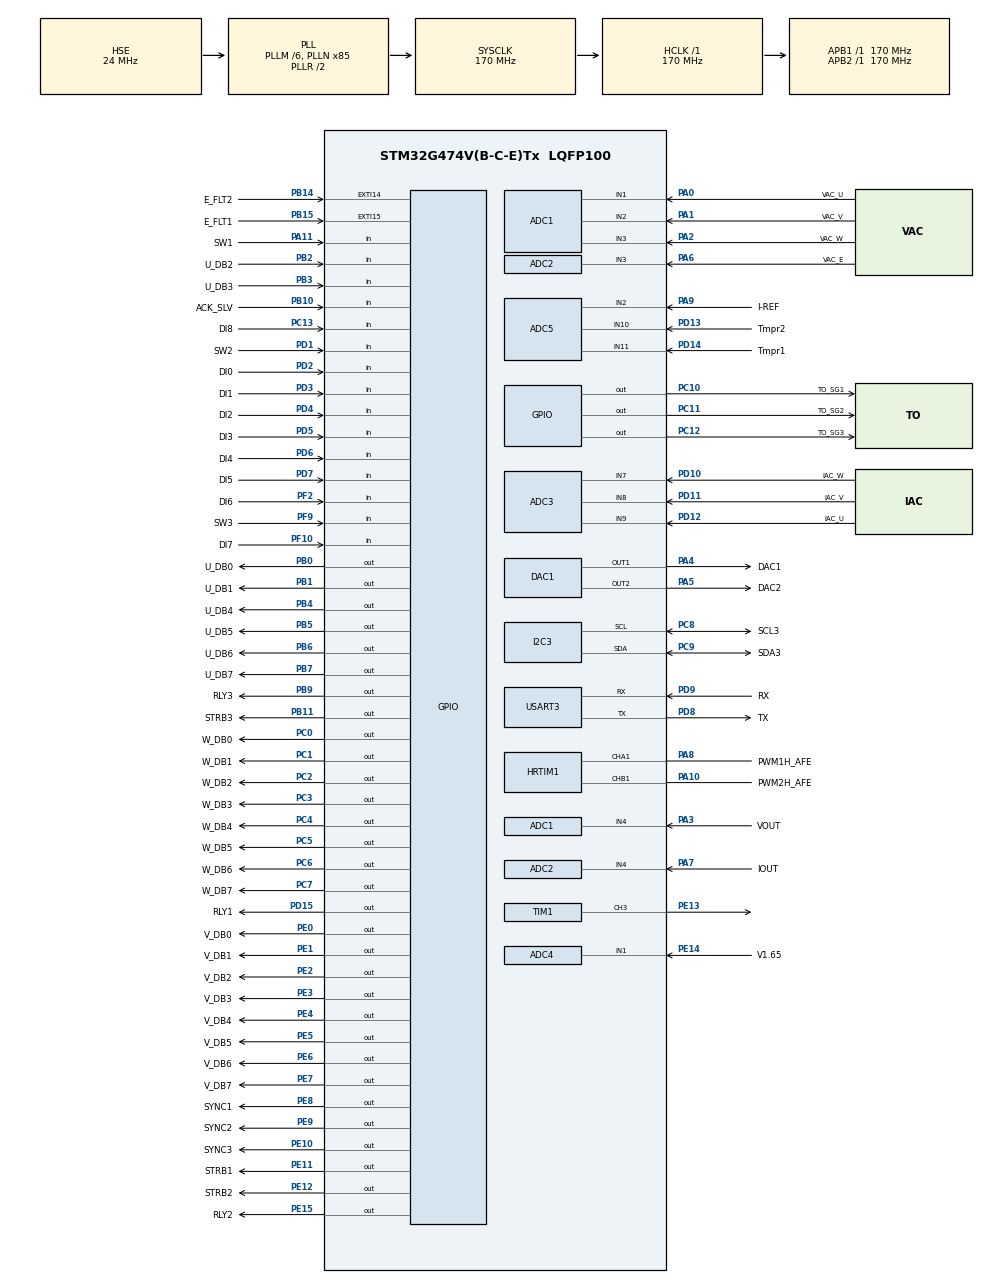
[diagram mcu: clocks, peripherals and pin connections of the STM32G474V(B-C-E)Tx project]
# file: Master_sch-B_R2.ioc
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ADC1.Channel-2\#ChannelRegularConversion=ADC_CHANNEL_1
ADC1.Channel-3\#ChannelRegularConversion=ADC_CHANNEL_3
ADC1.Channel-4\#ChannelRegularConversion=ADC_CHANNEL_2
ADC1.Channel-5\#ChannelRegularConversion=ADC_CHANNEL_4
ADC1.ContinuousConvMode=DISABLE
ADC1.DMAContinuousRequests=ENABLE
ADC1.EOCSelection=ADC_EOC_SEQ_CONV
ADC1.ExternalTrigConv=ADC_EXTERNALTRIG_T3_TRGO
ADC1.NbrOfConversion=4
ADC1.NbrOfConversionFlag=1
ADC1.OffsetNumber-2\#ChannelRegularConversion=ADC_OFFSET_NONE
ADC1.OffsetNumber-3\#ChannelRegularConversion=ADC_OFFSET_NONE
ADC1.OffsetNumber-4\#ChannelRegularConversion=ADC_OFFSET_NONE
ADC1.OffsetNumber-5\#ChannelRegularConversion=ADC_OFFSET_NONE
ADC1.Overrun=ADC_OVR_DATA_OVERWRITTEN
ADC1.Rank-2\#ChannelRegularConversion=1
ADC1.Rank-3\#ChannelRegularConversion=2
ADC1.Rank-4\#ChannelRegularConversion=3
ADC1.Rank-5\#ChannelRegularConversion=4
ADC1.SamplingTime-2\#ChannelRegularConversion=ADC_SAMPLETIME_2CYCLES_5
ADC1.SamplingTime-3\#ChannelRegularConversion=ADC_SAMPLETIME_2CYCLES_5
ADC1.SamplingTime-4\#ChannelRegularConversion=ADC_SAMPLETIME_2CYCLES_5
ADC1.SamplingTime-5\#ChannelRegularConversion=ADC_SAMPLETIME_2CYCLES_5
ADC1.master=1
ADC2.Channel-2\#ChannelRegularConversion=ADC_CHANNEL_3
ADC2.Channel-3\#ChannelRegularConversion=ADC_CHANNEL_4
ADC2.ContinuousConvMode=DISABLE
ADC2.DMAContinuousRequests=ENABLE
ADC2.ExternalTrigConv=ADC_EXTERNALTRIG_T3_TRGO
ADC2.LowPowerAutoWait=DISABLE
ADC2.NbrOfConversion=2
ADC2.NbrOfConversionFlag=1
ADC2.OffsetNumber-2\#ChannelRegularConversion=ADC_OFFSET_NONE
ADC2.OffsetNumber-3\#ChannelRegularConversion=ADC_OFFSET_NONE
ADC2.Rank-2\#ChannelRegularConversion=1
ADC2.Rank-3\#ChannelRegularConversion=2
ADC2.SamplingTime-2\#ChannelRegularConversion=ADC_SAMPLETIME_2CYCLES_5
ADC2.SamplingTime-3\#ChannelRegularConversion=ADC_SAMPLETIME_2CYCLES_5
ADC3.Channel-0\#ChannelRegularConversion=ADC_CHANNEL_9
ADC3.Channel-1\#ChannelRegularConversion=ADC_CHANNEL_7
ADC3.Channel-2\#ChannelRegularConversion=ADC_CHANNEL_8
ADC3.ContinuousConvMode=DISABLE
ADC3.DMAContinuousRequests=ENABLE
ADC3.ExternalTrigConv=ADC_EXTERNALTRIG_T3_TRGO
ADC3.NbrOfConversion=3
ADC3.NbrOfConversionFlag=1
ADC3.OffsetNumber-0\#ChannelRegularConversion=ADC_OFFSET_NONE
ADC3.OffsetNumber-1\#ChannelRegularConversion=ADC_OFFSET_NONE
ADC3.OffsetNumber-2\#ChannelRegularConversion=ADC_OFFSET_NONE
ADC3.Rank-0\#ChannelRegularConversion=1
ADC3.Rank-1\#ChannelRegularConversion=2
ADC3.Rank-2\#ChannelRegularConversion=3
ADC3.SamplingTime-0\#ChannelRegularConversion=ADC_SAMPLETIME_2CYCLES_5
ADC3.SamplingTime-1\#ChannelRegularConversion=ADC_SAMPLETIME_2CYCLES_5
ADC3.SamplingTime-2\#ChannelRegularConversion=ADC_SAMPLETIME_2CYCLES_5
ADC3.master=1
ADC4.Channel-1\#ChannelRegularConversion=ADC_CHANNEL_1
ADC4.DMAContinuousRequests=ENABLE
ADC4.NbrOfConversionFlag=1
ADC4.OffsetNumber-1\#ChannelRegularConversion=ADC_OFFSET_NONE
ADC4.Rank-1\#ChannelRegularConversion=1
ADC4.SamplingTime-1\#ChannelRegularConversion=ADC_SAMPLETIME_2CYCLES_5
ADC5.Channel-3\#ChannelRegularConversion=ADC_CHANNEL_2
ADC5.Channel-4\#ChannelRegularConversion=ADC_CHANNEL_10
ADC5.Channel-5\#ChannelRegularConversion=ADC_CHANNEL_11
ADC5.ContinuousConvMode=DISABLE
ADC5.DMAContinuousRequests=ENABLE
ADC5.NbrOfConversion=3
ADC5.NbrOfConversionFlag=1
ADC5.OffsetNumber-3\#ChannelRegularConversion=ADC_OFFSET_NONE
ADC5.OffsetNumber-4\#ChannelRegularConversion=ADC_OFFSET_NONE
ADC5.OffsetNumber-5\#ChannelRegularConversion=ADC_OFFSET_NONE
ADC5.Rank-3\#ChannelRegularConversion=1
ADC5.Rank-4\#ChannelRegularConversion=2
ADC5.Rank-5\#ChannelRegularConversion=3
ADC5.SamplingTime-3\#ChannelRegularConversion=ADC_SAMPLETIME_2CYCLES_5
ADC5.SamplingTime-4\#ChannelRegularConversion=ADC_SAMPLETIME_2CYCLES_5
ADC5.SamplingTime-5\#ChannelRegularConversion=ADC_SAMPLETIME_2CYCLES_5
DAC1.DAC_Channel-DAC_OUT2=DAC_CHANNEL_2
Dma.ADC1.1.Direction=DMA_PERIPH_TO_MEMORY
Dma.ADC1.1.EventEnable=DISABLE
Dma.ADC1.1.Instance=DMA1_Channel1
Dma.ADC1.1.MemDataAlignment=DMA_MDATAALIGN_HALFWORD
Dma.ADC1.1.MemInc=DMA_MINC_ENABLE
Dma.ADC1.1.Mode=DMA_CIRCULAR
Dma.ADC1.1.PeriphDataAlignment=DMA_PDATAALIGN_HALFWORD
Dma.ADC1.1.PeriphInc=DMA_PINC_DISABLE
Dma.ADC1.1.Polarity=HAL_DMAMUX_REQ_GEN_RISING
Dma.ADC1.1.Priority=DMA_PRIORITY_LOW
Dma.ADC1.1.RequestNumber=1
Dma.ADC1.1.SignalID=NONE
Dma.ADC1.1.SyncEnable=DISABLE
Dma.ADC1.1.SyncPolarity=HAL_DMAMUX_SYNC_NO_EVENT
Dma.ADC1.1.SyncRequestNumber=1
Dma.ADC1.1.SyncSignalID=NONE
Dma.ADC2.2.Direction=DMA_PERIPH_TO_MEMORY
Dma.ADC2.2.EventEnable=DISABLE
Dma.ADC2.2.Instance=DMA1_Channel3
Dma.ADC2.2.MemDataAlignment=DMA_MDATAALIGN_HALFWORD
Dma.ADC2.2.MemInc=DMA_MINC_ENABLE
Dma.ADC2.2.Mode=DMA_CIRCULAR
Dma.ADC2.2.PeriphDataAlignment=DMA_PDATAALIGN_HALFWORD
Dma.ADC2.2.PeriphInc=DMA_PINC_DISABLE
Dma.ADC2.2.Polarity=HAL_DMAMUX_REQ_GEN_RISING
Dma.ADC2.2.Priority=DMA_PRIORITY_LOW
Dma.ADC2.2.RequestNumber=1
Dma.ADC2.2.SignalID=NONE
Dma.ADC2.2.SyncEnable=DISABLE
Dma.ADC2.2.SyncPolarity=HAL_DMAMUX_SYNC_NO_EVENT
Dma.ADC2.2.SyncRequestNumber=1
Dma.ADC2.2.SyncSignalID=NONE
Dma.ADC3.0.Direction=DMA_PERIPH_TO_MEMORY
Dma.ADC3.0.EventEnable=DISABLE
Dma.ADC3.0.Instance=DMA1_Channel2
Dma.ADC3.0.MemDataAlignment=DMA_MDATAALIGN_HALFWORD
Dma.ADC3.0.MemInc=DMA_MINC_ENABLE
Dma.ADC3.0.Mode=DMA_CIRCULAR
Dma.ADC3.0.PeriphDataAlignment=DMA_PDATAALIGN_HALFWORD
Dma.ADC3.0.PeriphInc=DMA_PINC_DISABLE
Dma.ADC3.0.Polarity=HAL_DMAMUX_REQ_GEN_RISING
Dma.ADC3.0.Priority=DMA_PRIORITY_LOW
Dma.ADC3.0.RequestNumber=1
Dma.ADC3.0.SignalID=NONE
Dma.ADC3.0.SyncEnable=DISABLE
Dma.ADC3.0.SyncPolarity=HAL_DMAMUX_SYNC_NO_EVENT
Dma.ADC3.0.SyncRequestNumber=1
Dma.ADC3.0.SyncSignalID=NONE
Dma.ADC4.4.Direction=DMA_PERIPH_TO_MEMORY
Dma.ADC4.4.EventEnable=DISABLE
Dma.ADC4.4.Instance=DMA1_Channel4
Dma.ADC4.4.MemDataAlignment=DMA_MDATAALIGN_HALFWORD
Dma.ADC4.4.MemInc=DMA_MINC_ENABLE
Dma.ADC4.4.Mode=DMA_CIRCULAR
Dma.ADC4.4.PeriphDataAlignment=DMA_PDATAALIGN_HALFWORD
Dma.ADC4.4.PeriphInc=DMA_PINC_DISABLE
Dma.ADC4.4.Polarity=HAL_DMAMUX_REQ_GEN_RISING
Dma.ADC4.4.Priority=DMA_PRIORITY_LOW
Dma.ADC4.4.RequestNumber=1
Dma.ADC4.4.SignalID=NONE
Dma.ADC4.4.SyncEnable=DISABLE
Dma.ADC4.4.SyncPolarity=HAL_DMAMUX_SYNC_NO_EVENT
Dma.ADC4.4.SyncRequestNumber=1
Dma.ADC4.4.SyncSignalID=NONE
Dma.ADC5.3.Direction=DMA_PERIPH_TO_MEMORY
Dma.ADC5.3.EventEnable=DISABLE
Dma.ADC5.3.Instance=DMA1_Channel5
Dma.ADC5.3.MemDataAlignment=DMA_MDATAALIGN_HALFWORD
Dma.ADC5.3.MemInc=DMA_MINC_ENABLE
Dma.ADC5.3.Mode=DMA_CIRCULAR
Dma.ADC5.3.PeriphDataAlignment=DMA_PDATAALIGN_HALFWORD
Dma.ADC5.3.PeriphInc=DMA_PINC_DISABLE
Dma.ADC5.3.Polarity=HAL_DMAMUX_REQ_GEN_RISING
Dma.ADC5.3.Priority=DMA_PRIORITY_LOW
Dma.ADC5.3.RequestNumber=1
Dma.ADC5.3.SignalID=NONE
Dma.ADC5.3.SyncEnable=DISABLE
Dma.ADC5.3.SyncPolarity=HAL_DMAMUX_SYNC_NO_EVENT
Dma.ADC5.3.SyncRequestNumber=1
Dma.ADC5.3.SyncSignalID=NONE
Dma.Request0=ADC3
Dma.Request1=ADC1
Dma.Request2=ADC2
Dma.Request3=ADC5
Dma.Request4=ADC4
HRTIM1.CompareUnit1-MasterTimer=HRTIM_COMPAREUNIT_1
HRTIM1.CompareUnit1-Output_TA1=HRTIM_COMPAREUNIT_1
HRTIM1.CompareUnit1-Output_TB1=HRTIM_COMPAREUNIT_1
HRTIM1.CompareUnit2-MasterTimer=HRTIM_COMPAREUNIT_2
HRTIM1.CompareUnit2-Output_TA1=__NULL
HRTIM1.CompareUnit3-Output_TA1=HRTIM_COMPAREUNIT_3
HRTIM1.CompareUnit3-Output_TB1=HRTIM_COMPAREUNIT_3
HRTIM1.CompareValue1-MasterTimer=1
HRTIM1.CompareValue1-Output_TA1=0
HRTIM1.CompareValue1-Output_TB1=0
HRTIM1.CompareValue2-MasterTimer=17000
HRTIM1.CompareValue3-Output_TA1=1
HRTIM1.CompareValue3-Output_TB1=1
HRTIM1.GreaterCMP3_TA=HRTIM_TIMERGTCMP3_GREATER
HRTIM1.GreaterCMP3_TB=HRTIM_TIMERGTCMP3_GREATER
HRTIM1.NumberResetSource1-Output_TA1=1
HRTIM1.NumberResetSource1-Output_TB1=1
HRTIM1.NumberResetTrigger-Output_TA1=0
HRTIM1.NumberResetTrigger-Output_TB1=0
HRTIM1.NumberSetSource1-Output_TA1=1
HRTIM1.NumberSetSource1-Output_TB1=1
HRTIM1.Periode_MASTER=34000
HRTIM1.Periode_TA=17000
HRTIM1.Periode_TB=17000
HRTIM1.PrescalerRatio_MASTER=HRTIM_PRESCALERRATIO_DIV1
HRTIM1.PrescalerRatio_TA=HRTIM_PRESCALERRATIO_DIV1
HRTIM1.PrescalerRatio_TB=HRTIM_PRESCALERRATIO_DIV1
HRTIM1.ResetOutput1_Source1-Output_TA1=HRTIM_OUTPUTRESET_TIMCMP3
HRTIM1.ResetOutput1_Source1-Output_TB1=HRTIM_OUTPUTRESET_TIMCMP3
HRTIM1.SetOutput1_Source1-Output_TA1=HRTIM_OUTPUTSET_TIMCMP1
HRTIM1.SetOutput1_Source1-Output_TB1=HRTIM_OUTPUTSET_TIMCMP1
HRTIM1.SyncOptions=HRTIM_SYNCOPTION_MASTER
HRTIM1.UpDownMode-Output_TA1=HRTIM_TIMERUPDOWNMODE_UPDOWN
HRTIM1.UpDownMode-Output_TB1=HRTIM_TIMERUPDOWNMODE_UPDOWN
I2C3.Timing=0x30A0A7FB
Mcu.Family=STM32G4
Mcu.Name=STM32G474V(B-C-E)Tx
Mcu.Package=LQFP100
NVIC.PriorityGroup=NVIC_PRIORITYGROUP_4
NVIC.TIM3_IRQn=true\:0\:0\:false\:false\:true\:true\:true\:true
NVIC.TIM4_IRQn=true\:0\:0\:false\:false\:true\:true\:true\:true
NVIC.TIM6_DAC_IRQn=true\:0\:0\:false\:false\:true\:true\:true\:true
NVIC.TIM7_DAC_IRQn=true\:0\:0\:true\:false\:true\:true\:true\:true
PA0.GPIO_Label=VAC_U
PA0.Mode=IN1-Single-Ended
PA0.Signal=ADC1_IN1
PA1.GPIO_Label=VAC_V
PA1.Mode=IN2-Single-Ended
PA1.Signal=ADC1_IN2
PA10.GPIO_Label=PWM2H_AFE
PA10.Mode=Output_TB1
PA10.Signal=HRTIM1_CHB1
PA11.GPIO_Label=SW1
PA11.Signal=GPIO_Input
PA13.Mode=Serial_Wire
PA13.Signal=SYS_JTMS-SWDIO
PA14.Mode=Serial_Wire
PA14.Signal=SYS_JTCK-SWCLK
PA2.GPIO_Label=VAC_W
PA2.Mode=IN3-Single-Ended
PA2.Signal=ADC1_IN3
PA3.GPIO_Label=VOUT
PA3.Mode=IN4-Single-Ended
PA3.Signal=ADC1_IN4
PA4.GPIO_Label=DAC1
PA4.Signal=COMP_DAC11_group
PA5.GPIO_Label=DAC2
PA5.Signal=COMP_DAC12_group
PA6.GPIO_Label=VAC_E
PA6.Mode=IN3-Single-Ended
PA6.Signal=ADC2_IN3
PA7.GPIO_Label=IOUT
PA7.Mode=IN4-Single-Ended
PA7.Signal=ADC2_IN4
PA8.GPIO_Label=PWM1H_AFE
PA8.Mode=Output_TA1
PA8.Signal=HRTIM1_CHA1
PA9.GPIO_Label=I-REF
PA9.Mode=IN2-Single-Ended
PA9.Signal=ADC5_IN2
PB0.GPIO_Label=U_DB0
PB0.Signal=GPIO_Output
PB1.GPIO_Label=U_DB1
PB1.Signal=GPIO_Output
PB10.GPIO_Label=ACK_SLV
PB10.Signal=GPIO_Input
PB11.GPIO_Label=STRB3
PB11.Signal=GPIO_Output
PB14.GPIO_Label=E_FLT2
PB14.Signal=GPXTI14
PB15.GPIO_Label=E_FLT1
PB15.Signal=GPXTI15
PB2.GPIO_Label=U_DB2
PB2.GPIO_PuPd=GPIO_PULLUP
PB2.Signal=GPIO_Input
PB3.GPIO_Label=U_DB3
PB3.GPIO_PuPd=GPIO_PULLUP
PB3.Signal=GPIO_Input
PB4.GPIO_Label=U_DB4
PB4.GPIO_PuPd=GPIO_PULLDOWN
PB4.Signal=GPIO_Output
PB5.GPIO_Label=U_DB5
PB5.GPIO_PuPd=GPIO_PULLDOWN
PB5.Signal=GPIO_Output
PB6.GPIO_Label=U_DB6
PB6.Signal=GPIO_Output
PB7.GPIO_Label=U_DB7
PB7.Signal=GPIO_Output
PB9.GPIO_Label=RLY3
PB9.Signal=GPIO_Output
PC0.GPIO_Label=W_DB0
PC0.Signal=GPIO_Output
PC1.GPIO_Label=W_DB1
PC1.Signal=GPIO_Output
PC10.GPIO_Label=TO_SG1
PC10.Signal=GPIO_Output
PC11.GPIO_Label=TO_SG2
PC11.Signal=GPIO_Output
PC12.GPIO_Label=TO_SG3
PC12.Signal=GPIO_Output
PC13.GPIO_Label=DI8
PC13.Signal=GPIO_Input
PC14-OSC32_IN.Mode=LSE-External-Oscillator
PC14-OSC32_IN.Signal=RCC_OSC32_IN
PC15-OSC32_OUT.Mode=LSE-External-Oscillator
PC15-OSC32_OUT.Signal=RCC_OSC32_OUT
PC2.GPIO_Label=W_DB2
PC2.Signal=GPIO_Output
PC3.GPIO_Label=W_DB3
PC3.Signal=GPIO_Output
PC4.GPIO_Label=W_DB4
PC4.Signal=GPIO_Output
PC5.GPIO_Label=W_DB5
PC5.Signal=GPIO_Output
PC6.GPIO_Label=W_DB6
PC6.Signal=GPIO_Output
PC7.GPIO_Label=W_DB7
PC7.Signal=GPIO_Output
PC8.GPIO_Label=SCL3
PC8.Mode=I2C
PC8.Signal=I2C3_SCL
PC9.GPIO_Label=SDA3
PC9.Mode=I2C
PC9.Signal=I2C3_SDA
PD1.GPIO_Label=SW2
PD1.Signal=GPIO_Input
PD10.GPIO_Label=IAC_W
PD10.Mode=IN7-Single-Ended
PD10.Signal=ADC3_IN7
PD11.GPIO_Label=IAC_V
PD11.Mode=IN8-Single-Ended
PD11.Signal=ADC3_IN8
PD12.GPIO_Label=IAC_U
PD12.Mode=IN9-Single-Ended
PD12.Signal=ADC3_IN9
PD13.GPIO_Label=Tmpr2
PD13.Mode=IN10-Single-Ended
PD13.Signal=ADC5_IN10
PD14.GPIO_Label=Tmpr1
PD14.Mode=IN11-Single-Ended
PD14.Signal=ADC5_IN11
PD15.GPIO_Label=RLY1
PD15.Signal=GPIO_Output
PD2.GPIO_Label=DI0
PD2.Signal=GPIO_Input
PD3.GPIO_Label=DI1
PD3.Signal=GPIO_Input
PD4.GPIO_Label=DI2
PD4.Signal=GPIO_Input
PD5.GPIO_Label=DI3
PD5.Signal=GPIO_Input
PD6.GPIO_Label=DI4
PD6.Signal=GPIO_Input
PD7.GPIO_Label=DI5
PD7.Signal=GPIO_Input
PD8.GPIO_Label=TX
PD8.Mode=Asynchronous
PD8.Signal=USART3_TX
PD9.GPIO_Label=RX
PD9.Mode=Asynchronous
PD9.Signal=USART3_RX
PE0.GPIO_Label=V_DB0
PE0.Signal=GPIO_Output
PE1.GPIO_Label=V_DB1
PE1.Signal=GPIO_Output
PE10.GPIO_Label=SYNC3
PE10.Signal=GPIO_Output
PE11.GPIO_Label=STRB1
PE11.Signal=GPIO_Output
PE12.GPIO_Label=STRB2
PE12.Signal=GPIO_Output
PE13.Signal=S_TIM1_CH3
PE14.GPIO_Label=V1.65
PE14.Mode=IN1-Single-Ended
PE14.Signal=ADC4_IN1
PE15.GPIO_Label=RLY2
PE15.Signal=GPIO_Output
PE2.GPIO_Label=V_DB2
PE2.Signal=GPIO_Output
PE3.GPIO_Label=V_DB3
PE3.Signal=GPIO_Output
PE4.GPIO_Label=V_DB4
PE4.Signal=GPIO_Output
PE5.GPIO_Label=V_DB5
PE5.Signal=GPIO_Output
PE6.GPIO_Label=V_DB6
PE6.Signal=GPIO_Output
PE7.GPIO_Label=V_DB7
PE7.Signal=GPIO_Output
PE8.GPIO_Label=SYNC1
PE8.Signal=GPIO_Output
PE9.GPIO_Label=SYNC2
PE9.Signal=GPIO_Output
PF0-OSC_IN.Mode=HSE-External-Oscillator
PF0-OSC_IN.Signal=RCC_OSC_IN
PF1-OSC_OUT.Mode=HSE-External-Oscillator
PF1-OSC_OUT.Signal=RCC_OSC_OUT
PF10.GPIO_Label=DI7
PF10.Signal=GPIO_Input
PF2.GPIO_Label=DI6
PF2.Signal=GPIO_Input
PF9.GPIO_Label=SW3
PF9.Signal=GPIO_Input
ProjectManager.HeapSize=0x200
ProjectManager.StackSize=0x400
ProjectManager.TargetToolchain=STM32CubeIDE
RCC.ADC12Freq_Value=170000000
RCC.ADC345Freq_Value=170000000
RCC.AHBFreq_Value=170000000
RCC.APB1Freq_Value=170000000
RCC.APB1TimFreq_Value=170000000
RCC.APB2Freq_Value=170000000
RCC.APB2TimFreq_Value=170000000
RCC.CortexFreq_Value=170000000
RCC.EXTERNAL_CLOCK_VALUE=12288000
RCC.HCLKFreq_Value=170000000
RCC.HSE_VALUE=24000000
RCC.HSI48_VALUE=48000000
RCC.HSI_VALUE=16000000
RCC.PLLM=RCC_PLLM_DIV6
RCC.PLLN=85
RCC.PLLSourceVirtual=RCC_PLLSOURCE_HSE
RCC.SYSCLKFreq_VALUE=170000000
RCC.SYSCLKSource=RCC_SYSCLKSOURCE_PLLCLK
RCC.USBFreq_Value=170000000
RCC.VCOOutputFreq_Value=340000000
SH.COMP_DAC11_group.0=DAC1_OUT1,DAC_OUT1
SH.COMP_DAC12_group.0=DAC1_OUT2,DAC_OUT2
SH.S_TIM1_CH3.0=TIM1_CH3,PWM Generation3 CH3
TIM1.Channel-PWM\ Generation3\ CH3=TIM_CHANNEL_3
TIM1.PeriodNoDither=30000-1
TIM1.PulseNoDither_3=15000
TIM1.TIM_MasterOutputTrigger=TIM_TRGO_UPDATE
TIM3.TIM_MasterOutputTrigger=TIM_TRGO_UPDATE
TIM4.AutoReloadPreload=TIM_AUTORELOAD_PRELOAD_ENABLE
TIM4.PeriodNoDither=34000-1
TIM4.Prescaler=1-0
TIM6.AutoReloadPreload=TIM_AUTORELOAD_PRELOAD_ENABLE
TIM6.PeriodNoDither=34000-1
TIM6.Prescaler=5-1
USART3.VirtualMode-Asynchronous=VM_ASYNC
VP_HRTIM1_VS_hrtimMasterTimerNoOutput.Mode=MasterTimer
VP_SYS_VS_DBSignals.Mode=DisableDeadBatterySignals
VP_TIM16_VS_ClockSourceINT.Mode=Enable_Timer
VP_TIM1_VS_ClockSourceINT.Mode=Internal
VP_TIM3_VS_ClockSourceINT.Mode=Internal
VP_TIM4_VS_ClockSourceINT.Mode=Internal
VP_TIM6_VS_ClockSourceINT.Mode=Enable_Timer
VP_TIM7_VS_ClockSourceINT.Mode=Enable_Timer
board=custom

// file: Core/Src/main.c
/* USER CODE BEGIN Header */
/**
  ******************************************************************************
  * @file           : main.c
  * @brief          : Main program body
  ******************************************************************************
  * @attention
  *
  * Copyright (c) 2023 STMicroelectronics.
  * All rights reserved.
  *
  * This software is licensed under terms that can be found in the LICENSE file
  * in the root directory of this software component.
  * If no LICENSE file comes with this software, it is provided AS-IS.
  *
  ******************************************************************************
  */
/* USER CODE END Header */
#include "main.h"
#include "adc.h"
#include "dac.h"
#include "dma.h"
#include "hrtim.h"
#include "i2c.h"
#include "tim.h"
#include "usart.h"
#include "gpio.h"

/* USER CODE BEGIN Includes */
#include "process.h"
#include"i2cEeprom.h"
#include"debug.h"
#include "ntc_measurement.h"
#include "io.h"

#include "CAN1_Transmitting.h"
#include "CAN2_Transmitting.h"
#include "CAN3_Transmitting.h"
#include "CAN1_Receving.h"
#include "CAN2_Receving.h"
#include "CAN3_Receving.h"
#include "Can_Data_Xchange.h"
#include "protection.h"
#include "Slave_Monitoring.h"
#include "sequence.h"

/* USER CODE END Includes */

/* USER CODE BEGIN PV */

uint8_t u8MASTER_CAN1_Status,u8temp=1,u8temp1=1,u8MASTER_CAN2_Status;
//extern uint8_t u8Slave_1_CAN1_Live,u8Slave_2_CAN1_Live,u8Slave_3_CAN1_Live,u8Slave_1_CAN2_Live,u8Slave_2_CAN2_Live,u8Slave_3_CAN2_Live;
extern uint8_t can_debug_flag;

/* USER CODE END PV */

void SystemClock_Config(void);

int main(void)
{

  /* MCU Configuration--------------------------------------------------------*/

  /* Reset of all peripherals, Initializes the Flash interface and the Systick. */
  HAL_Init();

  /* USER CODE BEGIN Init */
  HAL_Delay(1000);
  /* USER CODE END Init */

  /* Configure the system clock */
  SystemClock_Config();

  /* Initialize all configured peripherals */
  MX_GPIO_Init();
  MX_DMA_Init();
  MX_USART3_UART_Init();
  MX_ADC1_Init();
  MX_ADC2_Init();
  MX_ADC3_Init();
  MX_ADC5_Init();
  MX_DAC1_Init();
  MX_TIM4_Init();
  MX_TIM6_Init();
  MX_TIM1_Init();
  MX_ADC4_Init();
  MX_I2C3_Init();
  MX_TIM7_Init();
  MX_TIM3_Init();
  MX_TIM16_Init();
  MX_HRTIM1_Init();
  /* USER CODE BEGIN 2 */

  generateAddress();
  if((masterAddress == 0) || (masterAddress > 6)){
	  criticalFault.bits.address_fault = 1;}

  //MX_FDCAN3_Init();
  default_para_load();

  Control_Init();
  InitLpfCo();

	ConfigPara.Kp_Vdc=0.2f;
	ConfigPara.Ki_Vdc=0.5f;
	ConfigPara.Kd_Vd = 0.01f;

	ConfigPara.Kp_Id=0.001f;
	ConfigPara.Ki_Id=0.001f;
	ConfigPara.Kd_Id = 0.01f;

	ConfigPara.Kp_Iq=0.001f;
	ConfigPara.Ki_Iq=0.001f;
	ConfigPara.Kd_Iq  = 0.01f;

  /* USER CODE END 2 */

  /* Infinite loop */
  while (1)
  {

    /* USER CODE BEGIN 3 */
	  //Task Executed at every 1 mSec

	  if (mSec1_Flag==1){
		  task_1ms();
	  }
	  //Task Executed at every 40 mSec
	  if (mSec40_Flag==1){
		  task_40ms();
	  }
	  // 0 success // 1 fail
	  //Task executed at every 100mS
	  if(mSec100_Flag == 1){
		  task_100ms();
	  }

	  // Task executed at every 250mS. Signals PSFB ready state
	  if(mSec250_Flag == 1){
		  task_250ms();
	  }

	  // Task Executed at every 1 Sec
	  if(Sec1_Flag==1){
		  task_1s();
	  }

	//  (u8temp==1) ? MX_FDCAN2_Init() : 0;
	  u8temp=0;

//	 (u8temp1==1) ? MX_FDCAN1_Init() : 0;
	  u8temp1=0;
  }
  /* USER CODE END 3 */
}

void SystemClock_Config(void)
{
  RCC_OscInitTypeDef RCC_OscInitStruct = {0};
  RCC_ClkInitTypeDef RCC_ClkInitStruct = {0};

  /** Configure the main internal regulator output voltage
  */
  HAL_PWREx_ControlVoltageScaling(PWR_REGULATOR_VOLTAGE_SCALE1_BOOST);

  /** Initializes the RCC Oscillators according to the specified parameters
  * in the RCC_OscInitTypeDef structure.
  */
  RCC_OscInitStruct.OscillatorType = RCC_OSCILLATORTYPE_HSE;
  RCC_OscInitStruct.HSEState = RCC_HSE_ON;
  RCC_OscInitStruct.PLL.PLLState = RCC_PLL_ON;
  RCC_OscInitStruct.PLL.PLLSource = RCC_PLLSOURCE_HSE;
  RCC_OscInitStruct.PLL.PLLM = RCC_PLLM_DIV6;
  RCC_OscInitStruct.PLL.PLLN = 85;
  RCC_OscInitStruct.PLL.PLLP = RCC_PLLP_DIV2;
  RCC_OscInitStruct.PLL.PLLQ = RCC_PLLQ_DIV2;
  RCC_OscInitStruct.PLL.PLLR = RCC_PLLR_DIV2;
  if (HAL_RCC_OscConfig(&RCC_OscInitStruct) != HAL_OK)
  {
    Error_Handler();
  }

  /** Initializes the CPU, AHB and APB buses clocks
  */
  RCC_ClkInitStruct.ClockType = RCC_CLOCKTYPE_HCLK|RCC_CLOCKTYPE_SYSCLK
                              |RCC_CLOCKTYPE_PCLK1|RCC_CLOCKTYPE_PCLK2;
  RCC_ClkInitStruct.SYSCLKSource = RCC_SYSCLKSOURCE_PLLCLK;
  RCC_ClkInitStruct.AHBCLKDivider = RCC_SYSCLK_DIV1;
  RCC_ClkInitStruct.APB1CLKDivider = RCC_HCLK_DIV1;
  RCC_ClkInitStruct.APB2CLKDivider = RCC_HCLK_DIV1;

  if (HAL_RCC_ClockConfig(&RCC_ClkInitStruct, FLASH_LATENCY_4) != HAL_OK)
  {
    Error_Handler();
  }
}

void Error_Handler(void)
{
  /* USER CODE BEGIN Error_Handler_Debug */
  /* User can add his own implementation to report the HAL error return state */
  __disable_irq();
  while (1)
  {
	  // Action to be decided
  }
  /* USER CODE END Error_Handler_Debug */
}
